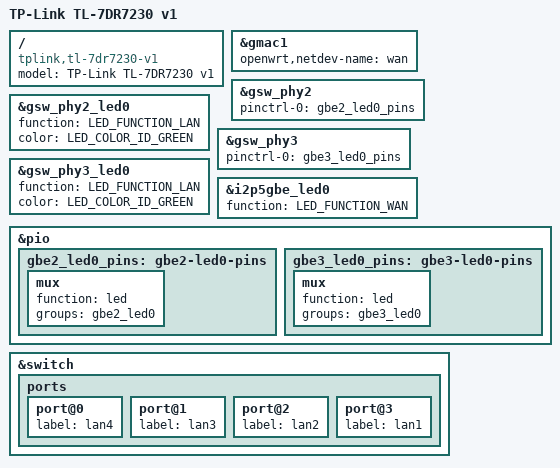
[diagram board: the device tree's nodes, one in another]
// SPDX-License-Identifier: GPL-2.0-or-later OR MIT
/*
 * Copyright (C) 2025 Tianling Shen <cnsztl@immortalwrt.org>
 */

/dts-v1/;
#include "mt7988d-tplink-tl-7dr-common.dtsi"

/ {
	model = "TP-Link TL-7DR7230 v1";
	compatible = "tplink,tl-7dr7230-v1", "mediatek,mt7988d";
};

&gmac1 {
	openwrt,netdev-name = "wan";
};

&gsw_phy2 {
	pinctrl-names = "gbe-led";
	pinctrl-0 = <&gbe2_led0_pins>;
};

&gsw_phy2_led0 {
	function = LED_FUNCTION_LAN;
	color = <LED_COLOR_ID_GREEN>;
	status = "okay";
};

&gsw_phy3 {
	pinctrl-names = "gbe-led";
	pinctrl-0 = <&gbe3_led0_pins>;
};

&gsw_phy3_led0 {
	function = LED_FUNCTION_LAN;
	color = <LED_COLOR_ID_GREEN>;
	status = "okay";
};

&i2p5gbe_led0 {
	function = LED_FUNCTION_WAN;
};

&pio {
	gbe2_led0_pins: gbe2-led0-pins {
		mux {
			function = "led";
			groups = "gbe2_led0";
		};
	};

	gbe3_led0_pins: gbe3-led0-pins {
		mux {
			function = "led";
			groups = "gbe3_led0";
		};
	};
};

&switch {
	ports {
		port@0 {
			label = "lan4";
		};

		port@1 {
			label = "lan3";
		};

		port@2 {
			label = "lan2";
		};

		port@3 {
			label = "lan1";
		};
	};
};
